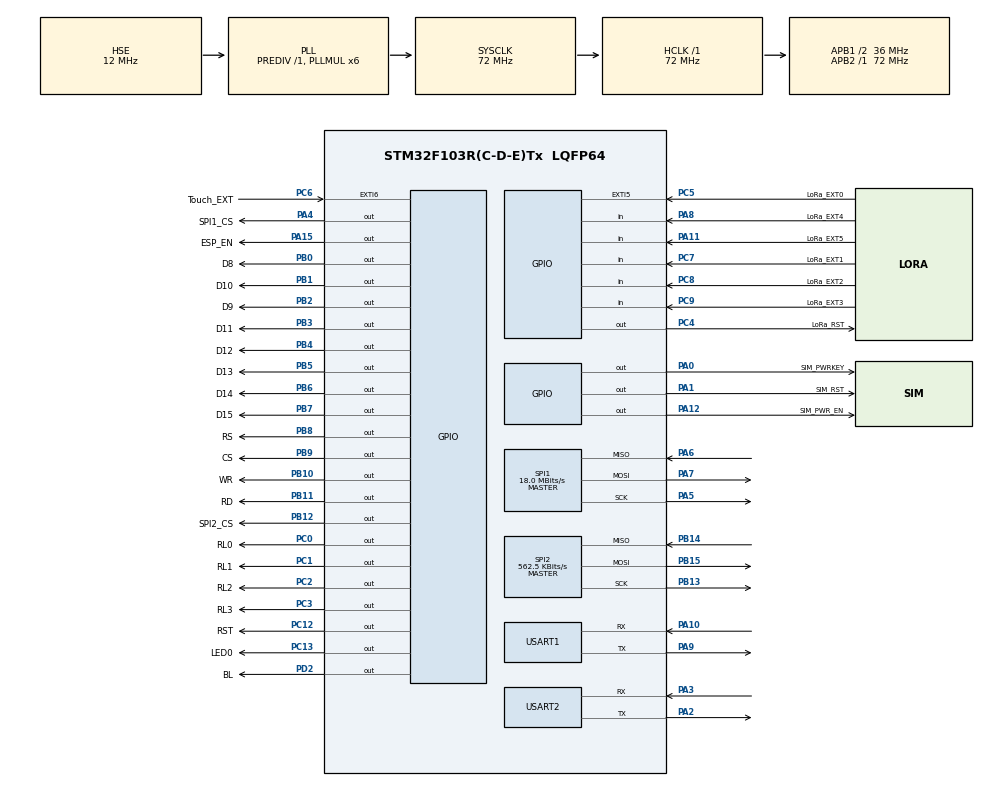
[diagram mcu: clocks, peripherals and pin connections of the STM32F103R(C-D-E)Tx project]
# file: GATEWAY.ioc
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FREERTOS.Tasks01=Task0,8,256,Task0Func,Default,NULL,Dynamic,NULL,NULL;Task1,24,512,Task1Func,Default,NULL,Dynamic,NULL,NULL;Task2,32,512,Task2Func,Default,NULL,Dynamic,NULL,NULL;Task3,16,512,Task3Func,Default,NULL,Dynamic,NULL,NULL
FREERTOS.configGENERATE_RUN_TIME_STATS=1
FREERTOS.configMINIMAL_STACK_SIZE=128
FREERTOS.configRECORD_STACK_HIGH_ADDRESS=1
FREERTOS.configTOTAL_HEAP_SIZE=10000
FREERTOS.configUSE_IDLE_HOOK=0
FREERTOS.configUSE_NEWLIB_REENTRANT=0
FREERTOS.configUSE_TICKLESS_IDLE=0
Mcu.Family=STM32F1
Mcu.Name=STM32F103R(C-D-E)Tx
Mcu.Package=LQFP64
NVIC.EXTI9_5_IRQn=true\:8\:0\:true\:false\:true\:true\:true\:true\:true
NVIC.PriorityGroup=NVIC_PRIORITYGROUP_4
NVIC.SPI1_IRQn=true\:5\:0\:false\:false\:true\:true\:true\:true\:true
NVIC.SPI2_IRQn=true\:5\:0\:false\:false\:true\:true\:true\:true\:true
NVIC.TIM1_UP_IRQn=true\:15\:0\:false\:false\:true\:false\:false\:true\:true
NVIC.TIM4_IRQn=true\:5\:0\:false\:false\:true\:true\:true\:true\:true
NVIC.TIM5_IRQn=true\:5\:0\:false\:false\:true\:true\:true\:true\:true
NVIC.TIM6_IRQn=true\:5\:0\:false\:false\:true\:true\:true\:true\:true
NVIC.TIM7_IRQn=true\:5\:0\:false\:false\:true\:true\:true\:true\:true
NVIC.TimeBase=TIM1_UP_IRQn
NVIC.TimeBaseIP=TIM1
NVIC.USART1_IRQn=true\:5\:0\:false\:false\:true\:true\:true\:true\:true
NVIC.USART2_IRQn=true\:5\:0\:false\:false\:true\:true\:true\:true\:true
PA0-WKUP.GPIO_Label=SIM_PWRKEY
PA0-WKUP.Signal=GPIO_Output
PA1.GPIO_Label=SIM_RST
PA1.Signal=GPIO_Output
PA10.Mode=Asynchronous
PA10.Signal=USART1_RX
PA11.GPIO_Label=LoRa_EXT5
PA11.Signal=GPIO_Input
PA12.GPIO_Label=SIM_PWR_EN
PA12.Signal=GPIO_Output
PA13.Mode=Serial_Wire
PA13.Signal=SYS_JTMS-SWDIO
PA14.Mode=Serial_Wire
PA14.Signal=SYS_JTCK-SWCLK
PA15.GPIO_Label=ESP_EN
PA15.GPIO_PuPd=GPIO_NOPULL
PA15.Signal=GPIO_Output
PA2.Mode=Asynchronous
PA2.Signal=USART2_TX
PA3.Mode=Asynchronous
PA3.Signal=USART2_RX
PA4.GPIO_Label=SPI1_CS
PA4.GPIO_Speed=GPIO_SPEED_FREQ_HIGH
PA4.Signal=GPIO_Output
PA5.Mode=Full_Duplex_Master
PA5.Signal=SPI1_SCK
PA6.Mode=Full_Duplex_Master
PA6.Signal=SPI1_MISO
PA7.Mode=Full_Duplex_Master
PA7.Signal=SPI1_MOSI
PA8.GPIO_Label=LoRa_EXT4
PA8.Signal=GPIO_Input
PA9.Mode=Asynchronous
PA9.Signal=USART1_TX
PB0.GPIO_Label=D8
PB0.GPIO_Speed=GPIO_SPEED_FREQ_HIGH
PB0.PinState=GPIO_PIN_SET
PB0.Signal=GPIO_Output
PB1.GPIO_Label=D10
PB1.GPIO_Speed=GPIO_SPEED_FREQ_HIGH
PB1.PinState=GPIO_PIN_SET
PB1.Signal=GPIO_Output
PB10.GPIO_Label=WR
PB10.GPIO_Speed=GPIO_SPEED_FREQ_HIGH
PB10.Signal=GPIO_Output
PB11.GPIO_Label=RD
PB11.GPIO_PuPd=GPIO_NOPULL
PB11.GPIO_Speed=GPIO_SPEED_FREQ_HIGH
PB11.Signal=GPIO_Output
PB12.GPIO_Label=SPI2_CS
PB12.GPIO_Speed=GPIO_SPEED_FREQ_HIGH
PB12.Signal=GPIO_Output
PB13.Mode=Full_Duplex_Master
PB13.Signal=SPI2_SCK
PB14.Mode=Full_Duplex_Master
PB14.Signal=SPI2_MISO
PB15.Mode=Full_Duplex_Master
PB15.Signal=SPI2_MOSI
PB2.GPIO_Label=D9
PB2.GPIO_Speed=GPIO_SPEED_FREQ_HIGH
PB2.PinState=GPIO_PIN_SET
PB2.Signal=GPIO_Output
PB3.GPIO_Label=D11
PB3.GPIO_Speed=GPIO_SPEED_FREQ_HIGH
PB3.PinState=GPIO_PIN_SET
PB3.Signal=GPIO_Output
PB4.GPIO_Label=D12
PB4.GPIO_Speed=GPIO_SPEED_FREQ_HIGH
PB4.PinState=GPIO_PIN_SET
PB4.Signal=GPIO_Output
PB5.GPIO_Label=D13
PB5.GPIO_Speed=GPIO_SPEED_FREQ_HIGH
PB5.PinState=GPIO_PIN_SET
PB5.Signal=GPIO_Output
PB6.GPIO_Label=D14
PB6.GPIO_Speed=GPIO_SPEED_FREQ_HIGH
PB6.PinState=GPIO_PIN_SET
PB6.Signal=GPIO_Output
PB7.GPIO_Label=D15
PB7.GPIO_Speed=GPIO_SPEED_FREQ_HIGH
PB7.PinState=GPIO_PIN_SET
PB7.Signal=GPIO_Output
PB8.GPIO_Label=RS
PB8.GPIO_Speed=GPIO_SPEED_FREQ_HIGH
PB8.Signal=GPIO_Output
PB9.GPIO_Label=CS
PB9.GPIO_Speed=GPIO_SPEED_FREQ_HIGH
PB9.Signal=GPIO_Output
PC0.GPIO_Label=RL0
PC0.GPIO_Speed=GPIO_SPEED_FREQ_LOW
PC0.Signal=GPIO_Output
PC1.GPIO_Label=RL1
PC1.Signal=GPIO_Output
PC12.GPIO_Label=RST
PC12.GPIO_Speed=GPIO_SPEED_FREQ_MEDIUM
PC12.PinState=GPIO_PIN_RESET
PC12.Signal=GPIO_Output
PC13-TAMPER-RTC.GPIO_Label=LED0
PC13-TAMPER-RTC.Signal=GPIO_Output
PC2.GPIO_Label=RL2
PC2.Signal=GPIO_Output
PC3.GPIO_Label=RL3
PC3.Signal=GPIO_Output
PC4.GPIO_Label=LoRa_RST
PC4.GPIO_Speed=GPIO_SPEED_FREQ_HIGH
PC4.Signal=GPIO_Output
PC5.GPIO_Label=LoRa_EXT0
PC5.GPIO_ModeDefaultEXTI=GPIO_MODE_IT_RISING
PC5.GPIO_PuPd=GPIO_PULLDOWN
PC5.Signal=GPXTI5
PC6.GPIO_Label=Touch_EXT
PC6.GPIO_ModeDefaultEXTI=GPIO_MODE_IT_FALLING
PC6.GPIO_PuPd=GPIO_PULLUP
PC6.Signal=GPXTI6
PC7.GPIO_Label=LoRa_EXT1
PC7.Signal=GPIO_Input
PC8.GPIO_Label=LoRa_EXT2
PC8.Signal=GPIO_Input
PC9.GPIO_Label=LoRa_EXT3
PC9.Signal=GPIO_Input
PD0-OSC_IN.Mode=HSE-External-Oscillator
PD0-OSC_IN.Signal=RCC_OSC_IN
PD1-OSC_OUT.Mode=HSE-External-Oscillator
PD1-OSC_OUT.Signal=RCC_OSC_OUT
PD2.GPIO_Label=BL
PD2.GPIO_PuPd=GPIO_PULLDOWN
PD2.GPIO_Speed=GPIO_SPEED_FREQ_MEDIUM
PD2.Signal=GPIO_Output
ProjectManager.HeapSize=0x200
ProjectManager.StackSize=0x400
ProjectManager.TargetToolchain=Makefile
RCC.AHBFreq_Value=72000000
RCC.APB1CLKDivider=RCC_HCLK_DIV2
RCC.APB1Freq_Value=36000000
RCC.APB1TimFreq_Value=72000000
RCC.APB2Freq_Value=72000000
RCC.APB2TimFreq_Value=72000000
RCC.HCLKFreq_Value=72000000
RCC.HSE_VALUE=12000000
RCC.PLLMUL=RCC_PLL_MUL6
RCC.PLLSourceVirtual=RCC_PLLSOURCE_HSE
RCC.SYSCLKFreq_VALUE=72000000
RCC.SYSCLKSource=RCC_SYSCLKSOURCE_PLLCLK
RCC.USBFreq_Value=48000000
RCC.USBPrescaler=RCC_USBCLKSOURCE_PLL_DIV1_5
RTC.Date=15
RTC.Format=RTC_FORMAT_BIN
RTC.Hours=19
RTC.Minutes=30
RTC.Month=RTC_MONTH_JULY
RTC.WeekDay=RTC_WEEKDAY_SATURDAY
RTC.Year=7
SPI1.BaudRatePrescaler=SPI_BAUDRATEPRESCALER_4
SPI1.CalculateBaudRate=18.0 MBits/s
SPI1.Direction=SPI_DIRECTION_2LINES
SPI1.Mode=SPI_MODE_MASTER
SPI1.VirtualType=VM_MASTER
SPI2.BaudRatePrescaler=SPI_BAUDRATEPRESCALER_64
SPI2.CalculateBaudRate=562.5 KBits/s
SPI2.Direction=SPI_DIRECTION_2LINES
SPI2.Mode=SPI_MODE_MASTER
SPI2.VirtualType=VM_MASTER
TIM4.Period=49999
TIM4.Prescaler=7199
TIM5.Period=99
TIM5.Prescaler=71
TIM6.Period=19999
TIM6.Prescaler=719
TIM7.Period=19999
TIM7.Prescaler=719
USART1.VirtualMode=VM_ASYNC
USART2.VirtualMode=VM_ASYNC
VP_FREERTOS_VS_CMSIS_V2.Mode=CMSIS_V2
VP_RTC_No_RTC_Output.Mode=RTC_OUT_NO
VP_RTC_VS_RTC_Activate.Mode=RTC_Enabled
VP_RTC_VS_RTC_Calendar.Mode=RTC_Calendar
VP_SYS_VS_tim1.Mode=TIM1
VP_TIM4_VS_ClockSourceINT.Mode=Internal
VP_TIM5_VS_ClockSourceINT.Mode=Internal
VP_TIM6_VS_ClockSourceINT.Mode=Enable_Timer
VP_TIM7_VS_ClockSourceINT.Mode=Enable_Timer
board=custom

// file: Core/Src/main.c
/* USER CODE BEGIN Header */
/**
  ******************************************************************************
  * @file           : main.c
  * @brief          : Main program body
  ******************************************************************************
  * @attention
  *
  * Copyright (c) 2023 STMicroelectronics.
  * All rights reserved.
  *
  * This software is licensed under terms that can be found in the LICENSE file
  * in the root directory of this software component.
  * If no LICENSE file comes with this software, it is provided AS-IS.
  *
  ******************************************************************************
  */
/* USER CODE END Header */
#include "main.h"
#include "cmsis_os.h"
#include "rtc.h"
#include "spi.h"
#include "tim.h"
#include "usart.h"
#include "gpio.h"

/* USER CODE BEGIN Includes */
#include "event_groups.h"
#include "common.h"
/* USER CODE END Includes */

void SystemClock_Config(void);
void MX_FREERTOS_Init(void);

int main(void)
{

  /* MCU Configuration--------------------------------------------------------*/

  /* Reset of all peripherals, Initializes the Flash interface and the Systick. */
  HAL_Init();

  /* Configure the system clock */
  SystemClock_Config();

  /* Initialize all configured peripherals */
  MX_GPIO_Init();
  MX_SPI1_Init();
  MX_SPI2_Init();
  MX_USART2_UART_Init();
  MX_RTC_Init();
  MX_USART1_UART_Init();
  MX_TIM7_Init();
  MX_TIM6_Init();
  MX_TIM5_Init();
  MX_TIM4_Init();
  /* USER CODE BEGIN 2 */
  NVIC_SetPriorityGrouping( NVIC_PRIORITYGROUP_4 );
  /* USER CODE END 2 */

  /* Init scheduler */
  osKernelInitialize();  /* Call init function for freertos objects (in freertos.c) */
  MX_FREERTOS_Init();

  /* Start scheduler */
  osKernelStart();
  /* We should never get here as control is now taken by the scheduler */
  /* Infinite loop */
  while (1)
  {

  }
}

void SystemClock_Config(void)
{
  RCC_OscInitTypeDef RCC_OscInitStruct = {0};
  RCC_ClkInitTypeDef RCC_ClkInitStruct = {0};
  RCC_PeriphCLKInitTypeDef PeriphClkInit = {0};

  /** Initializes the RCC Oscillators according to the specified parameters
  * in the RCC_OscInitTypeDef structure.
  */
  RCC_OscInitStruct.OscillatorType = RCC_OSCILLATORTYPE_LSI|RCC_OSCILLATORTYPE_HSE;
  RCC_OscInitStruct.HSEState = RCC_HSE_ON;
  RCC_OscInitStruct.HSEPredivValue = RCC_HSE_PREDIV_DIV1;
  RCC_OscInitStruct.HSIState = RCC_HSI_ON;
  RCC_OscInitStruct.LSIState = RCC_LSI_ON;
  RCC_OscInitStruct.PLL.PLLState = RCC_PLL_ON;
  RCC_OscInitStruct.PLL.PLLSource = RCC_PLLSOURCE_HSE;
  RCC_OscInitStruct.PLL.PLLMUL = RCC_PLL_MUL6;
  if (HAL_RCC_OscConfig(&RCC_OscInitStruct) != HAL_OK)
  {
    Error_Handler();
  }

  /** Initializes the CPU, AHB and APB buses clocks
  */
  RCC_ClkInitStruct.ClockType = RCC_CLOCKTYPE_HCLK|RCC_CLOCKTYPE_SYSCLK
                              |RCC_CLOCKTYPE_PCLK1|RCC_CLOCKTYPE_PCLK2;
  RCC_ClkInitStruct.SYSCLKSource = RCC_SYSCLKSOURCE_PLLCLK;
  RCC_ClkInitStruct.AHBCLKDivider = RCC_SYSCLK_DIV1;
  RCC_ClkInitStruct.APB1CLKDivider = RCC_HCLK_DIV2;
  RCC_ClkInitStruct.APB2CLKDivider = RCC_HCLK_DIV1;

  if (HAL_RCC_ClockConfig(&RCC_ClkInitStruct, FLASH_LATENCY_2) != HAL_OK)
  {
    Error_Handler();
  }
  PeriphClkInit.PeriphClockSelection = RCC_PERIPHCLK_RTC;
  PeriphClkInit.RTCClockSelection = RCC_RTCCLKSOURCE_LSI;
  if (HAL_RCCEx_PeriphCLKConfig(&PeriphClkInit) != HAL_OK)
  {
    Error_Handler();
  }
}

/* USER CODE BEGIN 4 */

extern bool is_UART1_RX_Done;
extern bool is_UART2_RX_Done;
extern uint64_t traceTime;

/* USER CODE END 4 */

void HAL_TIM_PeriodElapsedCallback(TIM_HandleTypeDef *htim)
{
  /* USER CODE BEGIN Callback 0 */
  if (htim->Instance == TIM7)
  {
    is_UART1_RX_Done = true;
    HAL_TIM_Base_Stop_IT(&htim7);
  }

  if (htim->Instance == TIM6)
  {
    is_UART2_RX_Done = true;
    HAL_TIM_Base_Stop_IT(&htim6);
  }

  if (htim->Instance == TIM5)
  {
    traceTime++;
  }

  if (htim->Instance == TIM4)
  {
    App_Refresh_Tick();
  }

  /* USER CODE END Callback 0 */
  if (htim->Instance == TIM1) {
    HAL_IncTick();
  }
}

void Error_Handler(void)
{
  __disable_irq();
  while (1)
  {
  }
}

#ifdef  USE_FULL_ASSERT
/**
  * @brief  Reports the name of the source file and the source line number
  *         where the assert_param error has occurred.
  * @param  file: pointer to the source file name
  * @param  line: assert_param error line source number
  * @retval None
  */
void assert_failed(uint8_t *file, uint32_t line)
{
  /* USER CODE BEGIN 6 */
  /* User can add his own implementation to report the file name and line number,
     ex: printf("Wrong parameters value: file %s on line %d\r\n", file, line) */
  logPC("Wrong parameters value: file %s on line %d", file, line);
  /* USER CODE END 6 */
}
#endif /* USE_FULL_ASSERT */

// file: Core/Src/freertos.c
/* USER CODE BEGIN Header */
/**
 ******************************************************************************
 * File Name          : freertos.c
 * Description        : Code for freertos applications
 ******************************************************************************
 * @attention
 *
 * Copyright (c) 2023 STMicroelectronics.
 * All rights reserved.
 *
 * This software is licensed under terms that can be found in the LICENSE file
 * in the root directory of this software component.
 * If no LICENSE file comes with this software, it is provided AS-IS.
 *
 ******************************************************************************
 */
/* USER CODE END Header */

#include "FreeRTOS.h"
#include "task.h"
#include "main.h"
#include "cmsis_os.h"

/* USER CODE BEGIN Includes */

#include "stdio.h"
#include "string.h"
#include "event_groups.h"
#include "semphr.h"

#include "usart.h"
#include "tim.h"
#include "rtc.h"

#include "lcd.h"
#include "pic.h"
#include "sx1278.h"
#include "common.h"
#include "sim.h"
#include "flash.h"
#include "button.h"
#include "mqtt.h"

/* USER CODE END Includes */

/* USER CODE BEGIN PTD */

typedef struct LoRa_Link_Struct
{
  uint16_t Node_ID;
  uint16_t Node_Status;
  uint16_t Node_Battery_Voltage;
  uint16_t Node_Period;
} Link_Struct_t;

typedef struct LoRa_Data_Struct
{
  Link_Struct_t Link;
  uint16_t Node_Soil_Temperature;
  uint16_t Node_Air_Temperature;
  uint16_t Node_Soil_Humidity;
  uint16_t Node_Air_Humidity;
  uint16_t Node_Salinity;
  uint16_t Node_Conductivity;
  uint16_t Node_pH;
  uint16_t Node_N;
  uint16_t Node_P;
  uint16_t Node_K;
} Data_Struct_t;

typedef struct LoRa_Packet_ID_0
{
  uint16_t Packet_ID;
  Link_Struct_t Payload;
} Link_Packet_t;

typedef struct LoRa_Packet_ID_1
{
  uint16_t Packet_ID;
  Data_Struct_t Payload;
} Data_Packet_t;

typedef struct LoRa_Packet_ID_2
{
  uint16_t Packet_ID;
  uint16_t Target_Node_ID;
  uint16_t Target_Node_Status;
  uint16_t Target_Node_Period;
  uint16_t Target_Node_Response;
} ResponsePacket_t;

typedef enum NodeStatus
{
  WAKEUP_MODE = 1U,
  LINK_MODE = 2U,
  NORMAL_MODE = 4U,
  RETRY_MODE = 8U,
  SHUTDOWN_MODE = 16U
} NodeStatus_t;

typedef enum Page_Enum
{
  MAIN_PAGE = 0U,
  JOIN_REQUEST_PAGE = 1U,
  NETWORK_PAGE = 2U,
  NODE_PAGE = 3U,
  CONTROL_PAGE = 4U,
  FAKE_PAGE = 133U
} Page_t;

typedef struct Time_Struct
{
  int	tm_sec;
  int	tm_min;
  int	tm_hour;
  int	tm_mday;
  int	tm_mon;
  int	tm_year;
  int	tm_wday;
  int	tm_yday;
  int	tm_isdst;
} Time_t;

/* USER CODE END PTD */

/* USER CODE BEGIN PD */

#define PACKET_ID_0   (0xAAAAU)
#define PACKET_ID_1   (0x5A5AU)
#define PACKET_ID_2   (0x5555U)

#define LINK_ACCEPT   (0xAAU)
#define LINK_REJECT   (0x55U)

#define LINK_CARRYON  (0x00U)
#define LINK_DISMISS  (0xFFU)

#define LINK_ACK      (0xABU)
#define LINK_NACK     (0xBAU)

#define DEFAULT_PERIOD_SEC  (300U)

// DO NOT CHANGE
#define EVT_LORA      (0x04U)
#define EVT_TOCUH     (0x02U)

// DO NOT CHANGE
#define MAX_NODE      (50U)

// WARNING: DO NOT CHANGE
#define USE_WIFI      (true)
#define USE_4G        (false)

/* USER CODE END PD */

/* USER CODE BEGIN Variables */

static uint8_t rxBufferUART1[200] = {0};
volatile static uint8_t rxIndexUART1 = 0;

static uint8_t rxBufferUART2[200] = {0};
volatile static uint8_t rxIndexUART2 = 0;

volatile bool is_UART1_RX_Done = true;
volatile bool is_UART2_RX_Done = true;
volatile bool is_LCD_processing = false;
volatile bool is_LoRa_processing = false;
volatile bool is_4G_or_WiFi = USE_WIFI;
volatile bool is_4G_connected = false;
volatile bool is_WiFi_connected = false;
volatile bool is_MQTT_connected = false;
volatile bool is_MQTT_update = false;
volatile bool is_promt_window_on = false;
volatile bool is_page_change = false;

static Data_Struct_t Node_Table[MAX_NODE] = {0};
static uint8_t number_of_Node_inNetwork = 0;
static uint8_t number_of_Node_inQueue = 0;
static uint8_t number_of_Response_Packet_inQueue = 0;
static uint16_t selected_Node_ID = 0;
static uint16_t updated_Node_ID = 0;

static EventGroupHandle_t evt_group;
static BaseType_t xHigherPriorityTaskWoken = pdFALSE;
static QueueHandle_t link_queue;
static QueueHandle_t response_queue;

volatile uint64_t traceTime = 0;

static Page_t Current_Page = MAIN_PAGE;
static uint16_t arrayNodeDisplay[4] = {0};
static char tempString[50] = {0};

const char link_mode_string[] = "LINK";
const char normal_mode_string[] = "NORMAL";
const char retry_mode_string[] = "RETRY";

/* USER CODE END Variables */
/* Definitions for Task0 */
osThreadId_t Task0Handle;
const osThreadAttr_t Task0_attributes = {
  .name = "Task0",
  .stack_size = 256 * 4,
  .priority = (osPriority_t) osPriorityLow,
};
/* Definitions for Task1 */
osThreadId_t Task1Handle;
const osThreadAttr_t Task1_attributes = {
  .name = "Task1",
  .stack_size = 512 * 4,
  .priority = (osPriority_t) osPriorityNormal,
};
/* Definitions for Task2 */
osThreadId_t Task2Handle;
const osThreadAttr_t Task2_attributes = {
  .name = "Task2",
  .stack_size = 512 * 4,
  .priority = (osPriority_t) osPriorityAboveNormal,
};
/* Definitions for Task3 */
osThreadId_t Task3Handle;
const osThreadAttr_t Task3_attributes = {
  .name = "Task3",
  .stack_size = 512 * 4,
  .priority = (osPriority_t) osPriorityBelowNormal,
};

/* USER CODE BEGIN FunctionPrototypes */

bool App_Add_Node_To_Network(Link_Struct_t link);
bool App_Delete_Node_From_Network(uint16_t Node_ID);

void App_SIM_MQTT_Parser(void);
void App_ESP_MQTT_Parser(void);

void App_ESP_getTime(void);

bool is_Node_ID_inLinkQueue(uint16_t Node_ID, bool remove);
bool is_Node_ID_inResponseQueue(uint16_t Node_ID, bool remove);
bool is_Node_ID_inNetwork(uint16_t Node_ID);
uint8_t get_Index_from_Node_ID(uint16_t Node_ID);
void LoRa_Packet_Parser(const uint8_t* data, uint32_t len);

void LCD_Print_Promt_Window(void);

void LCD_Print_Join_Request_Page(void);
void LCD_Join_Request_Page_Handle(const uint16_t x, const uint16_t y);

void LCD_Print_Main_Page(void);
void LCD_Main_Page_Handle(const uint16_t x, const uint16_t y);

void LCD_Print_Network_Page(void);
void LCD_Network_Page_Handle(const uint16_t x, const uint16_t y);

void LCD_Print_Node_Page(void);
void LCD_Node_Page_Handle(const uint16_t x, const uint16_t y);

void LCD_Print_Control_Page(void);
void LCD_Control_Page_Handle(const uint16_t x, const uint16_t y);

void LCD_Print_Fake_Page(void);
void LCD_Fake_Page_Handle(const uint16_t x, const uint16_t y);

/* USER CODE END FunctionPrototypes */

void Task0Func(void *argument);
void Task1Func(void *argument);
void Task2Func(void *argument);
void Task3Func(void *argument);

void MX_FREERTOS_Init(void); /* (MISRA C 2004 rule 8.1) */

/* Hook prototypes */
void configureTimerForRunTimeStats(void);
unsigned long getRunTimeCounterValue(void);

/* USER CODE BEGIN 1 */
/* Functions needed when configGENERATE_RUN_TIME_STATS is on */
__weak void configureTimerForRunTimeStats(void)
{
  HAL_TIM_Base_Start_IT(&htim5);
}

__weak unsigned long getRunTimeCounterValue(void)
{
  // uint32_t counter_now = __HAL_TIM_GetCounter(&htim5);
  // HAL_TIM_Base_Stop(&htim5);
  // __HAL_TIM_SET_COUNTER(&htim5, 0U);
  // HAL_TIM_Base_Start(&htim5);
  return traceTime;
}
/* USER CODE END 1 */

void MX_FREERTOS_Init(void) {
  /* USER CODE BEGIN Init */

  HAL_Delay(1500);
  Log_Init();
  /* USER CODE END Init */

  /* USER CODE BEGIN RTOS_SEMAPHORES */
  // lcd_semaphore = xSemaphoreCreateBinary();
  /* add semaphores, ... */
  /* USER CODE END RTOS_SEMAPHORES */

  /* Create the thread(s) */
  /* creation of Task0 */
  Task0Handle = osThreadNew(Task0Func, NULL, &Task0_attributes);

  /* creation of Task1 */
  Task1Handle = osThreadNew(Task1Func, NULL, &Task1_attributes);

  /* creation of Task2 */
  Task2Handle = osThreadNew(Task2Func, NULL, &Task2_attributes);

  /* creation of Task3 */
  Task3Handle = osThreadNew(Task3Func, NULL, &Task3_attributes);

  /* USER CODE BEGIN RTOS_THREADS */
  if ((Task0Handle == NULL) || (Task1Handle == NULL) || (Task2Handle == NULL) || (Task3Handle == NULL)) while(1);
  /* add threads, ... */
  /* USER CODE END RTOS_THREADS */

  /* USER CODE BEGIN RTOS_EVENTS */
  evt_group = xEventGroupCreate();
  if (evt_group == NULL) while(1);
  xEventGroupClearBits(evt_group, 0xFF);

  link_queue = xQueueCreate(MAX_NODE, sizeof(Link_Struct_t));
  if (link_queue == NULL) while(1);

  response_queue = xQueueCreate(5U, sizeof(ResponsePacket_t));
  if (response_queue == NULL) while(1);
  /* add events, ... */
  /* USER CODE END RTOS_EVENTS */

}

/* USER CODE BEGIN Header_Task0Func */
/**
 * @brief  Function implementing the Task0 thread.
 *
 *  This is the task to process UART (including ESP32) and helper functionalities
 *
 * @param  argument: Not used
 * @retval None
 */
/* USER CODE END Header_Task0Func */
void Task0Func(void *argument)
{
  /* USER CODE BEGIN Task0Func */
  static const char *TAG_LCD = "Utility";

  HAL_GPIO_WritePin(LED0_GPIO_Port, LED0_Pin, GPIO_PIN_RESET);
  HAL_Delay(200);
  HAL_GPIO_WritePin(LED0_GPIO_Port, LED0_Pin, GPIO_PIN_SET);

  HAL_UART_Receive_IT(&huart1, &rxBufferUART1[rxIndexUART1++], sizeof(uint8_t));

  HAL_TIM_Base_Stop_IT(&htim7);
  __HAL_TIM_SetCounter(&htim7, 0U);
  __HAL_TIM_CLEAR_IT(&htim7, TIM_IT_BREAK);

  HAL_UART_Receive_IT(&huart2, &rxBufferUART2[rxIndexUART2++], sizeof(uint8_t));

  HAL_TIM_Base_Stop_IT(&htim6);
  __HAL_TIM_SetCounter(&htim6, 0U);
  __HAL_TIM_CLEAR_IT(&htim6, TIM_IT_BREAK);

  static TaskStatus_t *pxTaskStatusArray;
	volatile static UBaseType_t uxArraySize, x;
	static unsigned long ulTotalRunTime;
	static float runtime_percent;

  HAL_Delay(500);

  if (is_4G_or_WiFi == USE_4G)    logPC("WIFI-OFF\t");
  if (is_4G_or_WiFi == USE_WIFI)  logPC("WIFI-ON\t");

  uint32_t timeKeeper0 = HAL_GetTick();
  uint32_t timeKeeper1 = HAL_GetTick();
  uint32_t timeKeeper2 = HAL_GetTick();
  /* Infinite loop */
  for (;;)
  {
    if ((is_UART1_RX_Done == true) && (rxIndexUART1 != 1))
    {
      logPC("UART1 RX - %s", rxBufferUART1);
      if      (strstr(rxBufferUART1, "WIFI-CONNECTED") != NULL)     {is_WiFi_connected = true;}
      else if (strstr(rxBufferUART1, "WIFI-DISCONNECTED") != NULL)  {is_WiFi_connected = false; is_MQTT_connected = false;}
      else if (strstr(rxBufferUART1, "MQTT-CONNECTED") != NULL)     {is_MQTT_connected = true; is_WiFi_connected = true;}
      else if (strstr(rxBufferUART1, "MQTT-DISCONNECTED") != NULL)  {is_MQTT_connected = false;}
      if      (strstr(rxBufferUART1, "MQTT-DATA") != NULL)          {App_ESP_MQTT_Parser();};
      if      (strstr(rxBufferUART1, "TIME-") != NULL)              {App_ESP_getTime();};
      rxIndexUART1 = 0;
      memset(rxBufferUART1, '\0', sizeof(rxBufferUART1));
      HAL_UART_Abort_IT(&huart1);
      HAL_UART_Receive_IT(&huart1, &rxBufferUART1[rxIndexUART1++], sizeof(uint8_t));
      HAL_GPIO_WritePin(LED0_GPIO_Port, LED0_Pin, GPIO_PIN_SET);
    }

    if ((is_UART2_RX_Done == true) && (rxIndexUART2 != 1))
    {
      logPC("UART2 RX - %s", rxBufferUART2);
      SIM_GetResponse((const char*)rxBufferUART2);
      rxIndexUART2 = 0;
      memset(rxBufferUART2, '\0', sizeof(rxBufferUART2));
      HAL_UART_Abort_IT(&huart2);
      HAL_UART_Receive_IT(&huart2, &rxBufferUART2[rxIndexUART2++], sizeof(uint8_t));
      HAL_GPIO_WritePin(LED0_GPIO_Port, LED0_Pin, GPIO_PIN_SET);
    }

    if ((is_MQTT_update == true) && (is_Node_ID_inNetwork(updated_Node_ID) == true) && (is_4G_or_WiFi == USE_WIFI) && (is_WiFi_connected == true) && (is_MQTT_connected == true))
    {
      HAL_UART_Transmit(&huart1, "MQTT-", 5U, 100);
      HAL_UART_Transmit(&huart1, &Node_Table[get_Index_from_Node_ID(updated_Node_ID)], sizeof(Data_Struct_t), 100);
      updated_Node_ID = 0xFFFF;
      is_MQTT_update = false;
    }

    if ((HAL_GetTick() - timeKeeper0) >= 3000)
    {
      if (is_LCD_processing == true)  is_LCD_processing = false;
      if (is_LoRa_processing == true)
      {
        sx1278_start_recv_data();
        xEventGroupClearBits(evt_group, EVT_LORA);
        is_LoRa_processing = false;
      }
      timeKeeper0 = HAL_GetTick();
    }

    if ((HAL_GetTick() - timeKeeper1) >= 60000)
    {
      uxArraySize = uxTaskGetNumberOfTasks();
      pxTaskStatusArray = pvPortMalloc(uxArraySize * sizeof(TaskStatus_t)); // a little bit scary!
      if (pxTaskStatusArray != NULL)
      {
        uxArraySize = uxTaskGetSystemState(pxTaskStatusArray, uxArraySize, &ulTotalRunTime);

        logPC("Task count = %lu\n", uxArraySize);
        logPC("No      Name          S Usage   HW\n");

        for (x = 0; x < uxArraySize; x++)
        {
          runtime_percent = (float) ((100 * (float)pxTaskStatusArray[x].ulRunTimeCounter) / (float)ulTotalRunTime);
          logPC("Task %lu: %-12s %2d %07.4f %4i\n", x, pxTaskStatusArray[x].pcTaskName, pxTaskStatusArray[x].eCurrentState, runtime_percent, pxTaskStatusArray[x].usStackHighWaterMark);
        }
        vPortFree(pxTaskStatusArray);
      }
      else  logPC("Unable to allocate stack space");
      timeKeeper1 = HAL_GetTick();
    }

    osDelay(10);
  }
  /* USER CODE END Task0Func */
}

/* USER CODE BEGIN Header_Task1Func */
/**
 * @brief Function implementing the Task1 thread.
 *
 *    This is the Task to process LCD display functionalities
 *
 * @param argument: Not used
 * @retval None
 */
/* USER CODE END Header_Task1Func */
void Task1Func(void *argument)
{
  /* USER CODE BEGIN Task1Func */
  static const char *TAG_LCD = "LCD";
  volatile static uint16_t coordinateX = 0;
  volatile static uint16_t coordinateY = 0;
  static EventBits_t evt_bits_lcd;
  xEventGroupClearBits(evt_group, EVT_TOCUH);

  ILI9341_Unselect();
  ILI9341_Init();
  LOG(TAG_LCD, "Initialize Done!\t");
  {
    uint32_t timeMark = HAL_GetTick();
    ILI9341_FillScreen(ILI9341_WHITE);
    timeMark = HAL_GetTick() - timeMark;
    logPC("%s - Screen Fill time: %d ms\tFPS: %2.1f\t", TAG_LCD, timeMark, (float)((1000.0)/(float)(timeMark)));
  }
  ILI9341_DrawImage(60, 45, 200, 150, (const uint16_t *)gLogoMain);
  osDelay(2000);
  // ILI9341_FillScreen(ILI9341_BLACK);
  is_page_change = true;
  LCD_Print_Main_Page();

  __HAL_TIM_SetCounter(&htim4, 0U);
  HAL_TIM_Base_Start_IT(&htim4);

  /* Infinite loop */
  for (;;)
  {
    evt_bits_lcd = xEventGroupWaitBits(evt_group, EVT_TOCUH, pdTRUE, pdFALSE, portMAX_DELAY);

    if(((evt_bits_lcd & EVT_TOCUH) != 0U) && (HAL_GPIO_ReadPin(Touch_EXT_GPIO_Port, Touch_EXT_Pin) == GPIO_PIN_RESET))
    {
      if (ILI9341_TouchGetCoordinates((uint16_t*)&coordinateX, (uint16_t*)&coordinateY) == true)
      {
        logPC("%s - Touched!\tCoordinate X - %d\tCoordinate Y - %d\t", TAG_LCD, coordinateX, coordinateY);
        switch (Current_Page)
        {
          case MAIN_PAGE: {
            LCD_Main_Page_Handle(coordinateX, coordinateY);
            break;
          }
          case JOIN_REQUEST_PAGE: {
            LCD_Join_Request_Page_Handle(coordinateX, coordinateY);
            break;
          }
          case NETWORK_PAGE: {
            LCD_Network_Page_Handle(coordinateX, coordinateY);
            break;
          }
          case NODE_PAGE: {
            LCD_Node_Page_Handle(coordinateX, coordinateY);
            break;
          }
          case CONTROL_PAGE: {
            LCD_Control_Page_Handle(coordinateX, coordinateY);
            break;
          }
          case FAKE_PAGE: {
            LCD_Fake_Page_Handle(coordinateX, coordinateY);
            break;
          }
          default: break;
        }
      }
    }

    // Refresh Page
    switch (Current_Page)
    {
      case MAIN_PAGE: {
        LCD_Print_Main_Page();
        break;
      }
      case JOIN_REQUEST_PAGE: {
        LCD_Print_Join_Request_Page();
        break;
      }
      case NETWORK_PAGE: {
        LCD_Print_Network_Page();
        break;
      }
      case NODE_PAGE: {
        LCD_Print_Node_Page();
        break;
      }
      case CONTROL_PAGE: {
        LCD_Print_Control_Page();
        break;
      }
      case FAKE_PAGE: {
        LCD_Print_Fake_Page();
        break;
      }
      default: break;
    }

    xEventGroupClearBits(evt_group, EVT_TOCUH);
    is_LCD_processing = false;
    osDelay(100);
  }
  /* USER CODE END Task1Func */
}

/* USER CODE BEGIN Header_Task2Func */
/**
 * @brief Function implementing the Task2 thread.
 *
 *    This is the Task to handle LoRa transceiver
 *
 * @param argument: Not used
 * @retval None
 */
/* USER CODE END Header_Task2Func */
void Task2Func(void *argument)
{
  /* USER CODE BEGIN Task2Func */
  static const char *TAG_LCD = "LoRa";
  static uint8_t data[100] = {0};
  static uint32_t nByteRx = 0;
  static int rssi = -1;
  static float snr = -1;
  static EventBits_t evt_bits;

  osDelay(1000);

  sx1278_init();
  sx1278_start_recv_data();

  /* Infinite loop */
  for (;;)
  {
    xEventGroupClearBits(evt_group, EVT_LORA);
    evt_bits = xEventGroupWaitBits(evt_group, EVT_LORA, pdTRUE, pdFALSE, portMAX_DELAY);

    if(((evt_bits & EVT_LORA) != 0U) && (HAL_GPIO_ReadPin(LoRa_EXT0_GPIO_Port, LoRa_EXT0_Pin) == GPIO_PIN_SET))
    {
      if (sx1278_recv_data((uint8_t *)data, &nByteRx, &rssi, &snr, true) == SX1278_OK)
      {
        logPC("LoRa Received %d byte(s)\trssi: %d\tsnr: %2.1f\n", nByteRx, rssi, snr);
        logPC("LoRa payload:\t");
        for (int i = 0; i < nByteRx; i++)
        {
          logPC("%02X ", data[i]);
        }
        LoRa_Packet_Parser((const uint8_t*)data, nByteRx);
      }
    }
    xEventGroupClearBits(evt_group, EVT_LORA);
    is_LoRa_processing = false;
    osDelay(1);
  }
  /* USER CODE END Task2Func */
}

/* USER CODE BEGIN Header_Task3Func */
/**
* @brief Function implementing the Task3 thread.
*
*     This is the Task to handle SIM4G functionalities
*
* @param argument: Not used
* @retval None
*/
/* USER CODE END Header_Task3Func */
void Task3Func(void *argument)
{
  /* USER CODE BEGIN Task3Func */
  static char temp[2][200];
  static char * pChar = NULL;
  static uint32_t len = 0;
  static Data_Struct_t data_to_send;
  static const char *TAG_LCD = "SIM";

  if (is_4G_or_WiFi != USE_4G)  osThreadTerminate(Task3Handle);

  osDelay(CMD_DELAY_SHORT);
  if (SIM_Init() == true)
  {
    if (SIM_checkSignalStrength() != 99U) {logPC("SIM signal OK");}
    else                                  {logPC("SIM signal FAIL");}

    if (SIM_startGPRS() == true)  {logPC("SIM 4G OK");}
    else                          {logPC("SIM 4G FAIL");}
  }
  osDelay(CMD_DELAY_SHORT);
  if (MQTT_Connect() == true)
  {
    setMQTT_Callback(MQTT_Callback);
    MQTT_Sub("SolGarden/Gateway/0x2508");
  }

  is_4G_connected = true;
  is_MQTT_connected = true;

  uint32_t timeKeeper = HAL_GetTick();

  /* Infinite loop */
  for(;;)
  {
    if ((HAL_GetTick() - timeKeeper) >= 30000)
    {
      MQTT_PingReq();
      timeKeeper = HAL_GetTick();
    }

    if ((is_4G_connected == true) && (is_MQTT_connected == true) && (is_MQTT_update == true) && (is_Node_ID_inNetwork(updated_Node_ID) == true))
    {
      memset(temp, '\0', sizeof(temp));

      data_to_send = Node_Table[get_Index_from_Node_ID(updated_Node_ID)];

      if      (data_to_send.Link.Node_Status == LINK_MODE)    pChar = &link_mode_string;
      else if (data_to_send.Link.Node_Status == NORMAL_MODE)  pChar = &normal_mode_string;
      else if (data_to_send.Link.Node_Status == RETRY_MODE)   pChar = &retry_mode_string;
      else                                                    {logPC("Invalid Status"); continue;}

      sprintf(&temp[0], "SolGarden/Node/%04X/link", data_to_send.Link.Node_ID);
      len = sprintf(  &temp[1], "[{\"Node ID\": \"0x%04X\",\"Node Mode\": \"%s\",\"Battery Voltage\": %d,\"Period\": %d}]",
                      data_to_send.Link.Node_ID,
                      pChar,
                      data_to_send.Link.Node_Battery_Voltage,
                      data_to_send.Link.Node_Period);
      logPC("MQTT - Topic: '%s'", temp[0]);
      logPC("MQTT - Payload: '%s'", temp[1]);
      MQTT_Pub(temp[0], temp[1]);

      memset(temp, '\0', sizeof(temp));
      osDelay(500);

      sprintf(&temp[0], "SolGarden/Node/%04X/data", data_to_send.Link.Node_ID);
      len = sprintf(  &temp[1], "[{\"Soil Temp.\": %2.1f,\"Air Temp.\": %2.1f,\"Soil Humd.\": %2.1f,\"Air Humd.\": %2.1f,\"Salinity\": %d,\"Conductivity\": %d,\"pH\": %.1f,\"N\": %d,\"P\": %d,\"K\": %d}]",
                      (float)(data_to_send.Node_Soil_Temperature/10.0),
                      (float)(data_to_send.Node_Air_Temperature/10.0),
                      (float)(data_to_send.Node_Soil_Humidity/10.0),
                      (float)(data_to_send.Node_Air_Humidity/10.0),
                      (uint16_t)data_to_send.Node_Salinity,
                      (uint16_t)data_to_send.Node_Conductivity,
                      (float)(data_to_send.Node_pH/10.0),
                      (uint16_t)(data_to_send.Node_N/10),
                      (uint16_t)(data_to_send.Node_P/10),
                      (uint16_t)(data_to_send.Node_K/10));
      logPC("MQTT - Topic: '%s'", temp[0]);
      logPC("MQTT - Payload: '%s'", temp[1]);
      MQTT_Pub(temp[0], temp[1]);

      osDelay(500);
      updated_Node_ID = 0xFFFF;
      is_MQTT_update = false;
      timeKeeper = HAL_GetTick();
    }

    if (MQTT.mqttReceive.newEvent == 1)
    {
      logPC("Now parsing MQTT packet...");
      App_SIM_MQTT_Parser();
      MQTT.mqttReceive.newEvent = 0;
    }

    osDelay(200);
  }
  /* USER CODE END Task3Func */
}

/* USER CODE BEGIN Application */

void App_Refresh_Tick(void)
{
  HAL_TIM_Base_Stop_IT(&htim4);
  __HAL_TIM_SetCounter(&htim4, 0U);
  xEventGroupSetBitsFromISR(evt_group, EVT_TOCUH, &xHigherPriorityTaskWoken);
  is_LCD_processing = true;
  RTC_DateTypeDef DateToUpdate = {0};
  HAL_RTC_GetDate(&hrtc, &DateToUpdate, RTC_FORMAT_BIN);
  uint32_t reg = (DateToUpdate.WeekDay << 16U) | (DateToUpdate.Month << 12U) | (DateToUpdate.Date << 7U) | (DateToUpdate.Year);
  HAL_RTCEx_BKUPWrite(&hrtc, RTC_BKP_DR1, reg);
  HAL_TIM_Base_Start_IT(&htim4);
}

bool App_Add_Node_To_Network(Link_Struct_t link)
{
  if (number_of_Node_inNetwork == MAX_NODE) return false;
  for (int i = 0; i < MAX_NODE; i++)
  {
    if (Node_Table[i].Link.Node_ID == 0U)
    {
      Node_Table[i].Link = link;
      number_of_Node_inNetwork++;
      return true;
    }
  }
  return false;
}

bool App_Delete_Node_From_Network(uint16_t Node_ID)
{
  Data_Struct_t data = {0};
  memset(&data, '\0', sizeof(Data_Struct_t));
  for (int i = 0; i < MAX_NODE; i++)
  {
    if (Node_Table[i].Link.Node_ID == Node_ID)
    {
      Node_Table[i] = data;
      number_of_Node_inNetwork--;
      return true;
    }
  }
  return false;
}

bool App_Save_Data(Data_Struct_t data)
{
  // if ()
  for (int i = 0; i < MAX_NODE; i++)
  {
    if (Node_Table[i].Link.Node_ID == data.Link.Node_ID)
    {
      Node_Table[i] = data;
      return true;
    }
  }
  return false;
}

void App_SIM_MQTT_Parser(void)
{
  logPC("MQTT Receive through SIM\t");
}

void App_ESP_MQTT_Parser(void)
{
  logPC("MQTT Receive through ESP\t");
}

void App_ESP_getTime(void)
{
  Time_t timeNow = {0};
  RTC_TimeTypeDef sTime = {0};
  RTC_DateTypeDef sDate = {0};

  memcpy(&timeNow, (uint8_t*)strstr(rxBufferUART1, "TIME-")+5U, sizeof(Time_t));
  logPC("Getting time... Now is %02d/%02d/%02d %02d:%02d:%02d\t", timeNow.tm_mday, timeNow.tm_mon+1, timeNow.tm_year-100, timeNow.tm_hour, timeNow.tm_min, timeNow.tm_sec);

  sTime.Seconds = timeNow.tm_sec;
  sTime.Minutes = timeNow.tm_min;
  sTime.Hours = timeNow.tm_hour;

  sDate.Date = timeNow.tm_mday;
  sDate.Month = timeNow.tm_mon + 1;
  sDate.Year = timeNow.tm_year - 100;
  sDate.WeekDay = timeNow.tm_wday;

  if (HAL_RTC_SetTime(&hrtc, &sTime, RTC_FORMAT_BIN) != HAL_OK)  {Error_Handler();}
  if (HAL_RTC_SetDate(&hrtc, &sDate, RTC_FORMAT_BIN) != HAL_OK)  {Error_Handler();}
}

//-------------------------------------------------------------------------------------------------------------------

bool is_Node_ID_inLinkQueue(uint16_t Node_ID, bool remove)
{
  number_of_Node_inQueue = MAX_NODE - (uint8_t)uxQueueSpacesAvailable(link_queue);
  Link_Struct_t link_stored;
  for (int i = 0; i < number_of_Node_inQueue; i++)
  {
    xQueueReceive(link_queue, &link_stored, 100);
    if (link_stored.Node_ID == Node_ID)
    {
      if (remove == false)  xQueueSendToFront(link_queue, &link_stored, 100);
      return true;
    }
    else xQueueSend(link_queue, &link_stored, 100);
  }
  return false;
}

bool is_Node_ID_inResponseQueue(uint16_t Node_ID, bool remove)
{
  number_of_Response_Packet_inQueue = 5U - (uint8_t)uxQueueSpacesAvailable(response_queue);
  ResponsePacket_t resp_stored;
  for (int i = 0; i < number_of_Response_Packet_inQueue; i++)
  {
    xQueueReceive(response_queue, &resp_stored, 100);
    if (resp_stored.Target_Node_ID == Node_ID)
    {
      if (remove == false)  xQueueSendToFront(response_queue, &resp_stored, 100);
      return true;
    }
    else xQueueSend(response_queue, &resp_stored, 100);
  }
  return false;
}

bool is_Node_ID_inNetwork(uint16_t Node_ID)
{
  for (int i = 0; i < MAX_NODE; i++)
  {
    if (Node_Table[i].Link.Node_ID == Node_ID)  return true;
  }
  return false;
}

uint8_t get_Index_from_Node_ID(uint16_t Node_ID)
{
  if (Node_ID == 0)   return 0xFF;
  for (uint8_t i = 0; i < MAX_NODE; i++)
  {
    if (Node_Table[i].Link.Node_ID == Node_ID)  return i;
  }
  return 0xFF;
}

/**
 * @brief check communicate line for idle slot to talk
 *
 * @return true ok now TALK!
 * @return false <infinite loop with random delay time>
 */
bool listen_before_talk(void)
{
  EventBits_t evt_bits;
  uint8_t irq;
  uint32_t timeout = HAL_GetTick();
  is_LoRa_processing = false;
  while ((HAL_GetTick() - timeout) <= 4000)
  {
    xEventGroupClearBits(evt_group, EVT_LORA);
    sx1278_cad();
    evt_bits = xEventGroupWaitBits(evt_group, EVT_LORA, pdTRUE, pdFALSE, 1000);
    if ((evt_bits & EVT_LORA) != 0U)
    {
      logPC("LoRa - CAD Done\tTook: %i ms\t", HAL_GetTick() - timeout);
      irq = sx1278_read_reg(REG_IRQ_FLAGS);
      sx1278_write_reg(REG_IRQ_FLAGS, irq);
      if ((irq & 0x01) != 0U)
      {
        logPC("LoRa - CAD Detected\t");
        HAL_Delay(get_random_value(0, 50));
      }
      else
      {
        logPC("LoRa - CAD Clear\t");
        sx1278_set_irq(0x00);
        sx1278_standby();
        return true;
      }
    }
  }
  irq = sx1278_read_reg(REG_IRQ_FLAGS);
  sx1278_write_reg(REG_IRQ_FLAGS, irq);
  sx1278_set_irq(0x00);
  sx1278_standby();
  logPC("Listen FAIL...\t");
  return false;
}

void LoRa_Packet_Parser(const uint8_t* data, uint32_t len)
{
  // void *p = NULL;
  switch ((uint16_t)((data[0] << 8) & 0xFF00) | (uint16_t)(data[1] & 0x00FF))
  {
    case PACKET_ID_0: {
      if (len != sizeof(Link_Packet_t)) break;
      logPC("Link Packet\t");
      Link_Struct_t link_payload;
      memcpy((uint8_t *)&link_payload, (uint8_t *)&data[2], sizeof(Link_Struct_t));
      if ((is_Node_ID_inNetwork(link_payload.Node_ID) == true) && (is_Node_ID_inResponseQueue(link_payload.Node_ID, false) == false))
      {
        ResponsePacket_t resp = {PACKET_ID_2, link_payload.Node_ID, NORMAL_MODE, 180U, (uint16_t)(((LINK_ACCEPT << 8) & 0xFF00) | LINK_ACK)};
        xQueueSendToFront(response_queue, &resp, 100);
        logPC("Node already in Network -> Send promote!\t");
      }
      if (is_Node_ID_inResponseQueue(link_payload.Node_ID, false) == true)
      {
        ResponsePacket_t resp;
        xQueueReceive(response_queue, &resp, 100);
        if (resp.Target_Node_ID != link_payload.Node_ID)
        {
          logPC("Something went wrong...");
          xQueueSendToFront(response_queue, &resp, 100);
          break;
        }
        logPC("Response Ready...\t");
        if (listen_before_talk() == false)  xQueueSendToFront(response_queue, &resp, 100);
        else  {logPC("Sending packet...\t"); sx1278_send_data(&resp, sizeof(ResponsePacket_t)); logPC("Done!\n");}
        sx1278_start_recv_data();
        break;
      }
      if (is_Node_ID_inLinkQueue(link_payload.Node_ID, true) == false)  logPC("New Node! Send to Queue...\t");
      else                                                              logPC("Old Node...\t");
      xQueueSend(link_queue, &(link_payload), 100);
      number_of_Node_inQueue = MAX_NODE - (uint8_t)uxQueueSpacesAvailable(link_queue);
      if (number_of_Node_inQueue != MAX_NODE)   logPC("Link Queue has %d Node(s)\n", number_of_Node_inQueue);
      else                                      logPC("Link Queue Full\n");
      break;
    }
    case PACKET_ID_1: {
      if (len != sizeof(Data_Packet_t)) break;
      logPC("Data Packet\t");
      Data_Struct_t data_recv;
      memcpy((uint8_t *)&data_recv, (uint8_t *)&data[2], sizeof(Data_Struct_t));
      if (is_Node_ID_inNetwork(data_recv.Link.Node_ID) == true)
      {
        logPC("Node Registered -> Saving data... %s", (App_Save_Data(data_recv))? ("Success\t"):("Fail\t"));
        ResponsePacket_t resp = {PACKET_ID_2, data_recv.Link.Node_ID, NORMAL_MODE, 180U, (uint16_t)(((LINK_CARRYON << 8) & 0xFF00) | LINK_ACK)};
        logPC("Response Ready...\t");
        if (listen_before_talk() == false)  break;
        else  {logPC("Sending packet...\t"); sx1278_send_data(&resp, sizeof(ResponsePacket_t));}
        logPC("Done!\n");
        sx1278_start_recv_data();
        updated_Node_ID = data_recv.Link.Node_ID;
        is_MQTT_update = true;
      }
      else
      {
        logPC("Node Unregister -> Demote Node...\t");
        ResponsePacket_t resp = {PACKET_ID_2, data_recv.Link.Node_ID, LINK_MODE, 180U, (uint16_t)(((LINK_DISMISS << 8) & 0xFF00) | LINK_ACK)};
        logPC("Response Ready...\t");
        if (listen_before_talk() == false)  break;
        else  {logPC("Sending packet...\t"); sx1278_send_data(&resp, sizeof(ResponsePacket_t));}
        logPC("Done!\n");
        sx1278_start_recv_data();
      }
      break;
    }
    default: {
      logPC("???? Packet\n");
      break;
    }
  }
  return;
}

//-------------------------------------------------------------------------------------------------------------------

void HAL_GPIO_EXTI_Callback(uint16_t GPIO_Pin)
{
  if ((GPIO_Pin == LoRa_EXT0_Pin) && (HAL_GPIO_ReadPin(LoRa_EXT0_GPIO_Port, LoRa_EXT0_Pin) == GPIO_PIN_SET) && (is_LoRa_processing == false))
  {
    xEventGroupSetBitsFromISR(evt_group, EVT_LORA, &xHigherPriorityTaskWoken);
    is_LoRa_processing = true;
  }

  if ((GPIO_Pin == Touch_EXT_Pin) && (HAL_GPIO_ReadPin(Touch_EXT_GPIO_Port, Touch_EXT_Pin) == GPIO_PIN_RESET) && (is_LCD_processing == false))
  {
    xEventGroupSetBitsFromISR(evt_group, EVT_TOCUH, &xHigherPriorityTaskWoken);
    is_LCD_processing = true;
  }
}

void HAL_UART_RxCpltCallback(UART_HandleTypeDef *huart)
{
  if (huart->Instance == USART1)
  {
    HAL_TIM_Base_Stop_IT(&htim7);
    if ((is_UART1_RX_Done == true) && (rxIndexUART1 == 1))
    {
      HAL_GPIO_WritePin(LED0_GPIO_Port, LED0_Pin, GPIO_PIN_RESET);
      __HAL_TIM_CLEAR_IT(&htim7, TIM_IT_BREAK);
      is_UART1_RX_Done = false;
    }
    __HAL_TIM_SetCounter(&htim7, 0U);
    HAL_TIM_Base_Start_IT(&htim7);
    HAL_UART_Receive_IT(&huart1, &rxBufferUART1[rxIndexUART1++], sizeof(uint8_t));
  }

  if (huart->Instance == USART2)
  {
    HAL_TIM_Base_Stop_IT(&htim6);
    if ((is_UART2_RX_Done == true) && (rxIndexUART2 == 1))
    {
      HAL_GPIO_WritePin(LED0_GPIO_Port, LED0_Pin, GPIO_PIN_RESET);
      __HAL_TIM_CLEAR_IT(&htim6, TIM_IT_BREAK);
      is_UART2_RX_Done = false;
    }
    __HAL_TIM_SetCounter(&htim6, 0U);
    HAL_TIM_Base_Start_IT(&htim6);
    HAL_UART_Receive_IT(&huart2, &rxBufferUART2[rxIndexUART2++], sizeof(uint8_t));
  }
}

//-------------------------------------------------------------------------------------------------------------------

void LCD_Print_Promt_Window(void)
{
  if (Current_Page == JOIN_REQUEST_PAGE)
  {
    is_promt_window_on = true;
    ILI9341_UpdateButton(&Promt_Window);
    ILI9341_WriteString(Promt_Window.pos_x+12, Promt_Window.pos_y+10, "ALLOW REQUEST?", Font_11x18, ILI9341_RED, Promt_Window.color_on);
    sprintf(tempString, "Node ID %#04X", selected_Node_ID);
    ILI9341_WriteString(Promt_Window.pos_x+12, Promt_Window.pos_y+35, tempString, Font_11x18, ILI9341_BLACK, Promt_Window.color_on);
    ILI9341_UpdateButton(&Promt_Accept);
    ILI9341_WriteString(Promt_Accept.pos_x+7, Promt_Accept.pos_y+6, "Accept", Font_11x18, ILI9341_BLACK, Promt_Accept.color_on);
    ILI9341_UpdateButton(&Promt_Reject);
    ILI9341_WriteString(Promt_Reject.pos_x+7, Promt_Reject.pos_y+6, "Reject", Font_11x18, ILI9341_BLACK, Promt_Reject.color_on);
  }
  else if (Current_Page == NODE_PAGE)
  {
    is_promt_window_on = true;
    ILI9341_UpdateButton(&Promt_Window);
    ILI9341_WriteString(Promt_Window.pos_x+22, Promt_Window.pos_y+10, "DELETE NODE?", Font_11x18, ILI9341_RED, Promt_Window.color_on);
    sprintf(tempString, "Node ID %#04X", selected_Node_ID);
    ILI9341_WriteString(Promt_Window.pos_x+14, Promt_Window.pos_y+35, tempString, Font_11x18, ILI9341_BLACK, Promt_Window.color_on);
    ILI9341_UpdateButton(&Promt_Confirm);
    ILI9341_WriteString(Promt_Confirm.pos_x+7, Promt_Confirm.pos_y+6, "Confirm", Font_11x18, ILI9341_WHITE, Promt_Confirm.color_on);
  }
}

//-------------------------------------------------------------------------------------------------------------------

void LCD_Print_Join_Request_Page(void)
{
  memset(arrayNodeDisplay, '\0', sizeof(arrayNodeDisplay));
  Link_Struct_t link_stored;

  number_of_Node_inQueue = MAX_NODE - (uint8_t)uxQueueSpacesAvailable(link_queue);
  sprintf(tempString, "Join Request (%i)", number_of_Node_inQueue);

  if (is_page_change == true) ILI9341_FillScreen(ILI9341_BLACK);

  if (is_promt_window_on == true)   return;

  ILI9341_WriteString(80, 21, tempString, Font_11x18, ILI9341_YELLOW, ILI9341_BLACK);

  if (is_page_change == true) ILI9341_UpdateButton(&Back_Top_Left);
  ILI9341_WriteString(Back_Top_Left.pos_x-10, Back_Top_Left.pos_y-13, "<", Font_16x26, ILI9341_BLACK, Back_Top_Left.color_on);

  ILI9341_DrawRectangle(Button1.pos_x, Button1.pos_y, Button1.shape_w, Button1.shape_h, ILI9341_YELLOW);
  ILI9341_DrawRectangle(Button2.pos_x, Button2.pos_y, Button2.shape_w, Button2.shape_h, ILI9341_YELLOW);
  ILI9341_DrawRectangle(Button3.pos_x, Button3.pos_y, Button3.shape_w, Button3.shape_h, ILI9341_YELLOW);
  ILI9341_DrawRectangle(Button4.pos_x, Button4.pos_y, Button4.shape_w, Button4.shape_h, ILI9341_YELLOW);

  if (number_of_Node_inQueue >= 1)
  {
    xQueueReceive(link_queue, &link_stored, 100);
    arrayNodeDisplay[0] = link_stored.Node_ID;
    sprintf(tempString, "Node ID: %#04X", link_stored.Node_ID);
    ILI9341_WriteString(Button1.pos_x+22, Button1.pos_y+10, tempString, Font_7x10, ILI9341_GREEN, ILI9341_BLACK);
    sprintf(tempString, "Node Status: %d", link_stored.Node_Status);
    ILI9341_WriteString(Button1.pos_x+10, Button1.pos_y+35, tempString, Font_7x10, ILI9341_LIGHTBLUE, ILI9341_BLACK);
    sprintf(tempString, "Node Batt: % 4d mV", link_stored.Node_Battery_Voltage);
    ILI9341_WriteString(Button1.pos_x+10, Button1.pos_y+55, tempString, Font_7x10, ILI9341_LIGHTBLUE, ILI9341_BLACK);
    sprintf(tempString, "Node Period: % 4d s", link_stored.Node_Period);
    ILI9341_WriteString(Button1.pos_x+10, Button1.pos_y+75, tempString, Font_7x10, ILI9341_LIGHTBLUE, ILI9341_BLACK);
    xQueueSend(link_queue, &link_stored, 100);
  }
  if (number_of_Node_inQueue >= 2)
  {
    xQueueReceive(link_queue, &link_stored, 100);
    arrayNodeDisplay[1] = link_stored.Node_ID;
    sprintf(tempString, "Node ID: %#04X", link_stored.Node_ID);
    ILI9341_WriteString(Button2.pos_x+22, Button2.pos_y+10, tempString, Font_7x10, ILI9341_GREEN, ILI9341_BLACK);
    sprintf(tempString, "Node Status: %d", link_stored.Node_Status);
    ILI9341_WriteString(Button2.pos_x+10, Button2.pos_y+35, tempString, Font_7x10, ILI9341_LIGHTBLUE, ILI9341_BLACK);
    sprintf(tempString, "Node Batt: % 4d mV", link_stored.Node_Battery_Voltage);
    ILI9341_WriteString(Button2.pos_x+10, Button2.pos_y+55, tempString, Font_7x10, ILI9341_LIGHTBLUE, ILI9341_BLACK);
    sprintf(tempString, "Node Period: % 4d s", link_stored.Node_Period);
    ILI9341_WriteString(Button2.pos_x+10, Button2.pos_y+75, tempString, Font_7x10, ILI9341_LIGHTBLUE, ILI9341_BLACK);
    xQueueSend(link_queue, &link_stored, 100);
  }
  if (number_of_Node_inQueue >= 3)
  {
    xQueueReceive(link_queue, &link_stored, 100);
    arrayNodeDisplay[2] = link_stored.Node_ID;
    sprintf(tempString, "Node ID: %#04X", link_stored.Node_ID);
    ILI9341_WriteString(Button3.pos_x+22, Button3.pos_y+10, tempString, Font_7x10, ILI9341_GREEN, ILI9341_BLACK);
    sprintf(tempString, "Node Status: %d", link_stored.Node_Status);
    ILI9341_WriteString(Button3.pos_x+10, Button3.pos_y+35, tempString, Font_7x10, ILI9341_LIGHTBLUE, ILI9341_BLACK);
    sprintf(tempString, "Node Batt: % 4d mV", link_stored.Node_Battery_Voltage);
    ILI9341_WriteString(Button3.pos_x+10, Button3.pos_y+55, tempString, Font_7x10, ILI9341_LIGHTBLUE, ILI9341_BLACK);
    sprintf(tempString, "Node Period: % 4d s", link_stored.Node_Period);
    ILI9341_WriteString(Button3.pos_x+10, Button3.pos_y+75, tempString, Font_7x10, ILI9341_LIGHTBLUE, ILI9341_BLACK);
    xQueueSend(link_queue, &link_stored, 100);
  }
  if (number_of_Node_inQueue >= 4)
  {
    xQueueReceive(link_queue, &link_stored, 100);
    arrayNodeDisplay[3] = link_stored.Node_ID;
    sprintf(tempString, "Node ID: %#04X", link_stored.Node_ID);
    ILI9341_WriteString(Button4.pos_x+22, Button4.pos_y+10, tempString, Font_7x10, ILI9341_GREEN, ILI9341_BLACK);
    sprintf(tempString, "Node Status: %d", link_stored.Node_Status);
    ILI9341_WriteString(Button4.pos_x+10, Button4.pos_y+35, tempString, Font_7x10, ILI9341_LIGHTBLUE, ILI9341_BLACK);
    sprintf(tempString, "Node Batt: % 4d mV", link_stored.Node_Battery_Voltage);
    ILI9341_WriteString(Button4.pos_x+10, Button4.pos_y+55, tempString, Font_7x10, ILI9341_LIGHTBLUE, ILI9341_BLACK);
    sprintf(tempString, "Node Period: % 4d s", link_stored.Node_Period);
    ILI9341_WriteString(Button4.pos_x+10, Button4.pos_y+75, tempString, Font_7x10, ILI9341_LIGHTBLUE, ILI9341_BLACK);
    xQueueSend(link_queue, &link_stored, 100);
  }

  is_page_change = false;
}

void LCD_Join_Request_Page_Handle(const uint16_t x, const uint16_t y)
{
  if (is_promt_window_on == true)
  {
    if (ILI9341_checkButton(x, y, &Promt_Accept, false) == true)
    {
      ResponsePacket_t resp_packet;
      Link_Struct_t link_2_store;
      is_Node_ID_inResponseQueue(selected_Node_ID, true);
      is_Node_ID_inLinkQueue(selected_Node_ID, false);
      xQueueReceive(link_queue, &link_2_store, 100);
      number_of_Node_inQueue = MAX_NODE - (uint8_t)uxQueueSpacesAvailable(link_queue);
      if (number_of_Node_inQueue != MAX_NODE)   logPC("Link Queue has %d Node(s)\n", number_of_Node_inQueue);
      else                                      logPC("Link Queue Full\n");
      resp_packet.Packet_ID = PACKET_ID_2;
      resp_packet.Target_Node_ID = selected_Node_ID;
      resp_packet.Target_Node_Status = 4U;
      resp_packet.Target_Node_Period = 180U;
      resp_packet.Target_Node_Response = (uint16_t)(((uint16_t)(LINK_ACCEPT << 8) & 0xFF00) | LINK_ACK);
      xQueueSend(response_queue, &resp_packet, 100);
      number_of_Response_Packet_inQueue = 5U - (uint8_t)uxQueueSpacesAvailable(response_queue);
      if (number_of_Response_Packet_inQueue != 5U)    logPC("Response Queue has %d packet(s)\n", number_of_Response_Packet_inQueue);
      else                                            logPC("Response Queue Full\n");
      App_Add_Node_To_Network(link_2_store);
      ILI9341_FillRectangle(Promt_Window.pos_x, Promt_Window.pos_y, Promt_Window.shape_w, Promt_Window.shape_h, ILI9341_BLACK);
      is_page_change = true;
      LCD_Print_Join_Request_Page();
      is_promt_window_on = false;
    }
    else if (ILI9341_checkButton(x, y, &Promt_Reject, false) == true)
    {
      ResponsePacket_t resp_packet;
      is_Node_ID_inResponseQueue(selected_Node_ID, true);
      is_Node_ID_inLinkQueue(selected_Node_ID, true);
      number_of_Node_inQueue = MAX_NODE - (uint8_t)uxQueueSpacesAvailable(link_queue);
      if (number_of_Node_inQueue != MAX_NODE)   logPC("Link Queue has %d Node(s)\n", number_of_Node_inQueue);
      else                                      logPC("Link Queue Full\n");
      resp_packet.Packet_ID = PACKET_ID_2;
      resp_packet.Target_Node_ID = selected_Node_ID;
      resp_packet.Target_Node_Status = 16U;
      resp_packet.Target_Node_Period = 180U;
      resp_packet.Target_Node_Response = (uint16_t)(((uint16_t)(LINK_REJECT << 8) & 0xFF00) | LINK_ACK);
      xQueueSend(response_queue, &resp_packet, 100);
      number_of_Response_Packet_inQueue = 5U - (uint8_t)uxQueueSpacesAvailable(response_queue);
      if (number_of_Response_Packet_inQueue != 5U)    logPC("Response Queue has %d packet(s)\n", number_of_Response_Packet_inQueue);
      else                                            logPC("Response Queue Full\n");
      ILI9341_FillRectangle(Promt_Window.pos_x, Promt_Window.pos_y, Promt_Window.shape_w,Promt_Window.shape_h, ILI9341_BLACK);
      is_page_change = true;
      LCD_Print_Join_Request_Page();
      is_promt_window_on = false;
    }
    else if (ILI9341_checkButton(x, y, &Promt_Window, false) == false)
    {
      ILI9341_FillRectangle(Promt_Window.pos_x, Promt_Window.pos_y, Promt_Window.shape_w,Promt_Window.shape_h, ILI9341_BLACK);
      LCD_Print_Join_Request_Page();
      is_promt_window_on = false;
    }
    return;
  }

  if (ILI9341_checkButton(x, y, &Back_Top_Left, false) == true)
  {
    Current_Page = MAIN_PAGE;
    is_page_change = true;
  }

  if (number_of_Node_inQueue == 0)  return;

  if      ((ILI9341_checkButton(x, y, &Button1, false) == true) && (arrayNodeDisplay[0] != 0U))
  {
    selected_Node_ID = arrayNodeDisplay[0];
    LCD_Print_Promt_Window();
  }
  else if ((ILI9341_checkButton(x, y, &Button2, false) == true) && (arrayNodeDisplay[1] != 0U))
  {
    selected_Node_ID = arrayNodeDisplay[1];
    LCD_Print_Promt_Window();
  }
  else if ((ILI9341_checkButton(x, y, &Button3, false) == true) && (arrayNodeDisplay[2] != 0U))
  {
    selected_Node_ID = arrayNodeDisplay[2];
    LCD_Print_Promt_Window();
  }
  else if ((ILI9341_checkButton(x, y, &Button4, false) == true) && (arrayNodeDisplay[3] != 0U))
  {
    selected_Node_ID = arrayNodeDisplay[3];
    LCD_Print_Promt_Window();
  }
}

//-------------------------------------------------------------------------------------------------------------------

void LCD_Print_Main_Page(void)
{
  static RTC_TimeTypeDef sTime = {0};
  static RTC_DateTypeDef sDate = {0};

  HAL_RTC_GetTime(&hrtc, &sTime, RTC_FORMAT_BIN);
  HAL_RTC_GetDate(&hrtc, &sDate, RTC_FORMAT_BIN);

  memset(tempString, '\0', sizeof(tempString));

  if (is_page_change == true) ILI9341_FillScreen(ILI9341_BLACK);

  sprintf(tempString, "SIM:%s-%s", (is_4G_or_WiFi==USE_4G)? ("ON"):("OFF"), (is_4G_connected==true)? ("CON "):("DIS "));
  ILI9341_WriteString(20, 10, tempString, Font_7x10, ILI9341_YELLOW, ILI9341_BLACK);
  sprintf(tempString, "WIFI:%s-%s", (is_4G_or_WiFi==USE_WIFI)? ("ON"):("OFF"), (is_WiFi_connected==true)? ("CON "):("DIS "));
  ILI9341_WriteString(125, 10, tempString, Font_7x10, ILI9341_YELLOW, ILI9341_BLACK);
  sprintf(tempString, "MQTT:%s", (is_MQTT_connected==true)? ("CON"):("DIS"));
  ILI9341_WriteString(244, 10, tempString, Font_7x10, ILI9341_YELLOW, ILI9341_BLACK);

  sprintf(tempString, "%02i:%02i", sTime.Hours, sTime.Minutes);
  ILI9341_WriteString(120, 40, tempString, Font_16x26, ILI9341_PINK, ILI9341_BLACK);
  sprintf(tempString, "%02i/%02i/20%02i", sDate.Date, sDate.Month, sDate.Year);
  ILI9341_WriteString(105, 75, tempString, Font_11x18, ILI9341_DARKBLUE, ILI9341_BLACK);

  if (is_page_change == false) return;

  ILI9341_WriteString(80, 100, "SOL GARDEN", Font_16x26, ILI9341_YELLOW, ILI9341_BLACK);

  ILI9341_UpdateButton(&To_Join_Request_Page);
  ILI9341_WriteString(To_Join_Request_Page.pos_x-28, To_Join_Request_Page.pos_y-8, "JOIN>", Font_11x18, ILI9341_BLACK, To_Join_Request_Page.color_on);
  ILI9341_UpdateButton(&To_Network_Page);
  ILI9341_WriteString(To_Network_Page.pos_x-28, To_Network_Page.pos_y-8, "<NETW", Font_11x18, ILI9341_BLACK, To_Network_Page.color_on);
  ILI9341_UpdateButton(&To_Control_Page);
  ILI9341_WriteString(To_Control_Page.pos_x-38, To_Control_Page.pos_y-8, "CONTROL", Font_11x18, ILI9341_BLACK, To_Control_Page.color_on);

  if (is_page_change == true) {is_page_change = false;}
}

void LCD_Main_Page_Handle(const uint16_t x, const uint16_t y)
{
  if (ILI9341_checkButton(x, y, &To_Join_Request_Page, false) == true)
  {
    Current_Page = JOIN_REQUEST_PAGE;
    is_page_change = true;
  }
  else if (ILI9341_checkButton(x, y, &To_Network_Page, false) == true)
  {
    Current_Page = NETWORK_PAGE;
    is_page_change = true;
  }
  else if (ILI9341_checkButton(x, y, &To_Control_Page, false) == true)
  {
    Current_Page = CONTROL_PAGE;
    is_page_change = true;
  }
  else if ((ILI9341_checkButton(x, y, &Select_4G, false) == true) && (is_4G_or_WiFi == USE_WIFI))
  {
    is_4G_or_WiFi = USE_4G;
    if (uxTaskGetNumberOfTasks() < 6) {Task3Handle = osThreadNew(Task3Func, NULL, &Task3_attributes);}
    is_4G_connected = false;
    is_WiFi_connected = false;
    is_MQTT_connected = false;
    logPC("\tChoose 4G\tWIFI-OFF\t");
  }
  else if ((ILI9341_checkButton(x, y, &Select_WiFi, false) == true) && (is_4G_or_WiFi == USE_4G))
  {
    is_4G_or_WiFi = USE_WIFI;
    if (uxTaskGetNumberOfTasks() >= 6) {osThreadTerminate(Task3Handle);}
    SIM_Deinit();
    is_4G_connected = false;
    is_WiFi_connected = false;
    is_MQTT_connected = false;
    logPC("\tChoose WiFi\tWIFI-ON\t");
  }
}

//-------------------------------------------------------------------------------------------------------------------

void LCD_Print_Network_Page(void)
{
  sprintf(tempString, "Network (%i)", number_of_Node_inNetwork);
  memset(arrayNodeDisplay, '\0', sizeof(arrayNodeDisplay));

  if (is_page_change == true) ILI9341_FillScreen(ILI9341_BLACK);

  if (is_page_change == true) ILI9341_UpdateButton(&FakeHehe);

  ILI9341_WriteString(105, 21, tempString, Font_11x18, ILI9341_YELLOW, ILI9341_BLACK);

  if (is_page_change == true) ILI9341_UpdateButton(&Back_Top_Right);
  ILI9341_WriteString(Back_Top_Right.pos_x-8, Back_Top_Right.pos_y-13, ">", Font_16x26, ILI9341_BLACK, Back_Top_Right.color_on);

  ILI9341_DrawRectangle(Button1.pos_x, Button1.pos_y, Button1.shape_w, Button1.shape_h, ILI9341_YELLOW);
  ILI9341_DrawRectangle(Button2.pos_x, Button2.pos_y, Button2.shape_w, Button2.shape_h, ILI9341_YELLOW);
  ILI9341_DrawRectangle(Button3.pos_x, Button3.pos_y, Button3.shape_w, Button3.shape_h, ILI9341_YELLOW);
  ILI9341_DrawRectangle(Button4.pos_x, Button4.pos_y, Button4.shape_w, Button4.shape_h, ILI9341_YELLOW);

  uint8_t loop = (number_of_Node_inNetwork >= 4)? (4):(number_of_Node_inNetwork);
  uint8_t idx = (uint8_t)get_random_value(0, MAX_NODE);
  for (uint8_t j = 0; j < loop; j++)
  {
    while (Node_Table[idx].Link.Node_ID == 0)
    {
      idx++;
      if (idx >= MAX_NODE)  idx = 0;
    }

    if (j == 0)
    {
      arrayNodeDisplay[0] = Node_Table[idx].Link.Node_ID;
      sprintf(tempString, "Node ID: %#04X", Node_Table[idx].Link.Node_ID);
      ILI9341_WriteString(Button1.pos_x+22, Button1.pos_y+10, tempString, Font_7x10, ILI9341_GREEN, ILI9341_BLACK);
      sprintf(tempString, "Node Status: %d", Node_Table[idx].Link.Node_Status);
      ILI9341_WriteString(Button1.pos_x+10, Button1.pos_y+35, tempString, Font_7x10, ILI9341_LIGHTBLUE, ILI9341_BLACK);
      sprintf(tempString, "Node Batt: % 4d mV", Node_Table[idx].Link.Node_Battery_Voltage);
      ILI9341_WriteString(Button1.pos_x+10, Button1.pos_y+55, tempString, Font_7x10, ILI9341_LIGHTBLUE, ILI9341_BLACK);
      sprintf(tempString, "Node Period: % 4d s", Node_Table[idx].Link.Node_Period);
      ILI9341_WriteString(Button1.pos_x+10, Button1.pos_y+75, tempString, Font_7x10, ILI9341_LIGHTBLUE, ILI9341_BLACK);
    }
    else if (j == 1)
    {
      arrayNodeDisplay[1] = Node_Table[idx].Link.Node_ID;
      sprintf(tempString, "Node ID: %#04X", Node_Table[idx].Link.Node_ID);
      ILI9341_WriteString(Button2.pos_x+22, Button2.pos_y+10, tempString, Font_7x10, ILI9341_GREEN, ILI9341_BLACK);
      sprintf(tempString, "Node Status: %d", Node_Table[idx].Link.Node_Status);
      ILI9341_WriteString(Button2.pos_x+10, Button2.pos_y+35, tempString, Font_7x10, ILI9341_LIGHTBLUE, ILI9341_BLACK);
      sprintf(tempString, "Node Batt: % 4d mV", Node_Table[idx].Link.Node_Battery_Voltage);
      ILI9341_WriteString(Button2.pos_x+10, Button2.pos_y+55, tempString, Font_7x10, ILI9341_LIGHTBLUE, ILI9341_BLACK);
      sprintf(tempString, "Node Period: % 4d s", Node_Table[idx].Link.Node_Period);
      ILI9341_WriteString(Button2.pos_x+10, Button2.pos_y+75, tempString, Font_7x10, ILI9341_LIGHTBLUE, ILI9341_BLACK);
    }
    else if (j == 2)
    {
      arrayNodeDisplay[2] = Node_Table[idx].Link.Node_ID;
      sprintf(tempString, "Node ID: %#04X", Node_Table[idx].Link.Node_ID);
      ILI9341_WriteString(Button3.pos_x+22, Button3.pos_y+10, tempString, Font_7x10, ILI9341_GREEN, ILI9341_BLACK);
      sprintf(tempString, "Node Status: %d", Node_Table[idx].Link.Node_Status);
      ILI9341_WriteString(Button3.pos_x+10, Button3.pos_y+35, tempString, Font_7x10, ILI9341_LIGHTBLUE, ILI9341_BLACK);
      sprintf(tempString, "Node Batt: % 4d mV", Node_Table[idx].Link.Node_Battery_Voltage);
      ILI9341_WriteString(Button3.pos_x+10, Button3.pos_y+55, tempString, Font_7x10, ILI9341_LIGHTBLUE, ILI9341_BLACK);
      sprintf(tempString, "Node Period: % 4d s", Node_Table[idx].Link.Node_Period);
      ILI9341_WriteString(Button3.pos_x+10, Button3.pos_y+75, tempString, Font_7x10, ILI9341_LIGHTBLUE, ILI9341_BLACK);
    }
    else if (j == 3)
    {
      arrayNodeDisplay[3] = Node_Table[idx].Link.Node_ID;
      sprintf(tempString, "Node ID: %#04X", Node_Table[idx].Link.Node_ID);
      ILI9341_WriteString(Button4.pos_x+22, Button4.pos_y+10, tempString, Font_7x10, ILI9341_GREEN, ILI9341_BLACK);
      sprintf(tempString, "Node Status: %d", Node_Table[idx].Link.Node_Status);
      ILI9341_WriteString(Button4.pos_x+10, Button4.pos_y+35, tempString, Font_7x10, ILI9341_LIGHTBLUE, ILI9341_BLACK);
      sprintf(tempString, "Node Batt: % 4d mV", Node_Table[idx].Link.Node_Battery_Voltage);
      ILI9341_WriteString(Button4.pos_x+10, Button4.pos_y+55, tempString, Font_7x10, ILI9341_LIGHTBLUE, ILI9341_BLACK);
      sprintf(tempString, "Node Period: % 4d s", Node_Table[idx].Link.Node_Period);
      ILI9341_WriteString(Button4.pos_x+10, Button4.pos_y+75, tempString, Font_7x10, ILI9341_LIGHTBLUE, ILI9341_BLACK);
    }

    idx++;
  }
  is_page_change = false;
}

void LCD_Network_Page_Handle(const uint16_t x, const uint16_t y)
{
  if ((ILI9341_checkButton(x, y, &FakeHehe, false) == true))
  {
    Current_Page = FAKE_PAGE;
    is_page_change = true;
    return;
  }
  if (ILI9341_checkButton(x, y, &Back_Top_Right, false) == true)
  {
    Current_Page = MAIN_PAGE;
    is_page_change = true;
  }
  else if ((ILI9341_checkButton(x, y, &Button1, false) == true) && (arrayNodeDisplay[0] != 0U))
  {
    selected_Node_ID = arrayNodeDisplay[0];
    Current_Page = NODE_PAGE;
    is_page_change = true;
  }
  else if ((ILI9341_checkButton(x, y, &Button2, false) == true) && (arrayNodeDisplay[1] != 0U))
  {
    selected_Node_ID = arrayNodeDisplay[1];
    Current_Page = NODE_PAGE;
    is_page_change = true;
  }
  else if ((ILI9341_checkButton(x, y, &Button3, false) == true) && (arrayNodeDisplay[2] != 0U))
  {
    selected_Node_ID = arrayNodeDisplay[2];
    Current_Page = NODE_PAGE;
    is_page_change = true;
  }
  else if ((ILI9341_checkButton(x, y, &Button4, false) == true) && (arrayNodeDisplay[3] != 0U))
  {
    selected_Node_ID = arrayNodeDisplay[3];
    Current_Page = NODE_PAGE;
    is_page_change = true;
  }
}

//-------------------------------------------------------------------------------------------------------------------

void LCD_Print_Node_Page(void)
{
  if (is_page_change == true) ILI9341_FillScreen(ILI9341_BLACK);

  if (is_promt_window_on == true)   return;

  Data_Struct_t data_stored = Node_Table[get_Index_from_Node_ID(selected_Node_ID)];

  if (is_page_change == true) ILI9341_UpdateButton(&Back_Top_Right);
  ILI9341_WriteString(Back_Top_Right.pos_x-8, Back_Top_Right.pos_y-13, ">", Font_16x26, ILI9341_BLACK, Back_Top_Right.color_on);

  if (is_page_change == true) ILI9341_UpdateButton(&Delete);
  ILI9341_WriteString(Delete.pos_x-5, Delete.pos_y-8, "X", Font_11x18, ILI9341_WHITE, Delete.color_on);

  sprintf(tempString, "NODE %#04X", selected_Node_ID);
  ILI9341_WriteString(105, 14, tempString, Font_11x18, ILI9341_YELLOW, ILI9341_BLACK);

  switch (data_stored.Link.Node_Status)
  {
    case (2U): {
      ILI9341_WriteString(75, 35, "Node Status: LINK", Font_11x18, ILI9341_CYAN, ILI9341_BLACK);
      break;
    }
    case (4U): {
      ILI9341_WriteString(65, 35, "Node Status: NORMAL", Font_11x18, ILI9341_GREEN, ILI9341_BLACK);
      break;
    }
    case (8U): {
      ILI9341_WriteString(75, 35, "Node Status: RETRY", Font_11x18, ILI9341_ORANGE, ILI9341_BLACK);
      break;
    }
    default: {
      ILI9341_WriteString(60, 35, "Node Status: UNKOWN", Font_11x18, ILI9341_RED, ILI9341_BLACK);
      break;
    }
  }

  sprintf(tempString, "Node Batt: % 4d mV", data_stored.Link.Node_Battery_Voltage);
  ILI9341_WriteString(15, 60, tempString, Font_7x10, ILI9341_YELLOW, ILI9341_BLACK);

  sprintf(tempString, "Node Period: % 4d s", data_stored.Link.Node_Period);
  ILI9341_WriteString(175, 60, tempString, Font_7x10, ILI9341_YELLOW, ILI9341_BLACK);

  if (data_stored.Link.Node_Status != 4U) {is_page_change = false; return;}

  sprintf(tempString, "Soil Temp.: % 2.1f dC", (float)(data_stored.Node_Soil_Temperature/10.0));
  ILI9341_WriteString(15, 100, tempString, Font_7x10, ILI9341_RED, ILI9341_BLACK);

  sprintf(tempString, "Air Temp.: % 2.1f dC", (float)(data_stored.Node_Air_Temperature/10.0));
  ILI9341_WriteString(175, 100, tempString, Font_7x10, ILI9341_RED, ILI9341_BLACK);

  sprintf(tempString, "Soil Humd.: % 2.1f %%RH", (float)(data_stored.Node_Soil_Humidity/10.0));
  ILI9341_WriteString(15, 120, tempString, Font_7x10, ILI9341_ORANGE, ILI9341_BLACK);

  sprintf(tempString, "Air Humd.: % 2.1f %%RH", (float)(data_stored.Node_Air_Humidity/10.0));
  ILI9341_WriteString(175, 120, tempString, Font_7x10, ILI9341_ORANGE, ILI9341_BLACK);

  sprintf(tempString, "Salinity: %d uS/cm", data_stored.Node_Salinity);
  ILI9341_WriteString(15, 140, tempString, Font_7x10, ILI9341_YELLOW, ILI9341_BLACK);

  sprintf(tempString, "Conductivity: %d uS/cm", data_stored.Node_Conductivity);
  ILI9341_WriteString(15, 160, tempString, Font_7x10, ILI9341_LIGHTGREEN, ILI9341_BLACK);

  sprintf(tempString, "pH: % 2.1f pH", (float)(data_stored.Node_pH/10.0));
  ILI9341_WriteString(15, 180, tempString, Font_7x10, ILI9341_LIGHTBLUE, ILI9341_BLACK);

  sprintf(tempString, "N: %d mg/kg", (uint16_t)(data_stored.Node_N/10));
  ILI9341_WriteString(175, 180, tempString, Font_7x10, ILI9341_LIGHTBLUE, ILI9341_BLACK);

  sprintf(tempString, "P: %d mg/kg", (uint16_t)(data_stored.Node_P/10));
  ILI9341_WriteString(15, 200, tempString, Font_7x10, ILI9341_PINK, ILI9341_BLACK);

  sprintf(tempString, "K: %d mg/kg", (uint16_t)(data_stored.Node_K/10));
  ILI9341_WriteString(175, 200, tempString, Font_7x10, ILI9341_PINK, ILI9341_BLACK);

  is_page_change = false;
}

void LCD_Node_Page_Handle(const uint16_t x, const uint16_t y)
{
  if (is_promt_window_on == true)
  {
    if (ILI9341_checkButton(x, y, &Promt_Confirm, false) == true)
    {
      App_Delete_Node_From_Network(selected_Node_ID);
      ILI9341_FillRectangle(Promt_Window.pos_x, Promt_Window.pos_y, Promt_Window.shape_w,Promt_Window.shape_h, ILI9341_BLACK);
      is_page_change = true;
      Current_Page = NETWORK_PAGE;
      is_promt_window_on = false;
    }
    else if (ILI9341_checkButton(x, y, &Promt_Window, false) == false)
    {
      ILI9341_FillRectangle(Promt_Window.pos_x, Promt_Window.pos_y, Promt_Window.shape_w,Promt_Window.shape_h, ILI9341_BLACK);
      Current_Page = NODE_PAGE;
      is_promt_window_on = false;
    }
    return;
  }

  if (ILI9341_checkButton(x, y, &Back_Top_Right, false) == true)
  {
    Current_Page = NETWORK_PAGE;
    is_page_change = true;
  }

  if (number_of_Node_inNetwork == 0)  return;

  if (ILI9341_checkButton(x, y, &Delete, false) == true)
  {
    LCD_Print_Promt_Window();
  }
}

//-------------------------------------------------------------------------------------------------------------------

void LCD_Print_Control_Page(void)
{
  if (is_page_change == true) {ILI9341_FillScreen(ILI9341_BLACK); is_page_change = false;}
  else return;

  ILI9341_UpdateButton(&To_Main_Page);
  ILI9341_WriteString(To_Main_Page.pos_x-22, To_Main_Page.pos_y-7, "MAIN", Font_11x18, ILI9341_WHITE, To_Main_Page.color_on);

  ILI9341_UpdateButton(&Button5);
  if (Button5.state == BUTTON_ON) ILI9341_WriteString(Button5.pos_x-16, Button5.pos_y-10, "ON", Font_16x26, ILI9341_BLACK, Button5.color_on);
  else                            ILI9341_WriteString(Button5.pos_x-24, Button5.pos_y-10, "OFF", Font_16x26, ILI9341_WHITE, Button5.color_off);
  ILI9341_WriteString(110, 10, "RL0", Font_11x18, ILI9341_YELLOW, ILI9341_BLACK);

  ILI9341_UpdateButton(&Button6);
  if (Button6.state == BUTTON_ON) ILI9341_WriteString(Button6.pos_x-16, Button6.pos_y-10, "ON", Font_16x26, ILI9341_BLACK, Button6.color_on);
  else                            ILI9341_WriteString(Button6.pos_x-24, Button6.pos_y-10, "OFF", Font_16x26, ILI9341_WHITE, Button6.color_off);
  ILI9341_WriteString(180, 10, "RL1", Font_11x18, ILI9341_YELLOW, ILI9341_BLACK);

  ILI9341_UpdateButton(&Button7);
  if (Button7.state == BUTTON_ON) ILI9341_WriteString(Button7.pos_x-16, Button7.pos_y-10, "ON", Font_16x26, ILI9341_BLACK, Button7.color_on);
  else                            ILI9341_WriteString(Button7.pos_x-24, Button7.pos_y-10, "OFF", Font_16x26, ILI9341_WHITE, Button7.color_off);
  ILI9341_WriteString(110, 210, "RL2", Font_11x18, ILI9341_YELLOW, ILI9341_BLACK);

  ILI9341_UpdateButton(&Button8);
  if (Button8.state == BUTTON_ON) ILI9341_WriteString(Button8.pos_x-16, Button8.pos_y-10, "ON", Font_16x26, ILI9341_BLACK, Button8.color_on);
  else                            ILI9341_WriteString(Button8.pos_x-24, Button8.pos_y-10, "OFF", Font_16x26, ILI9341_WHITE, Button8.color_off);
  ILI9341_WriteString(180, 210, "RL3", Font_11x18, ILI9341_YELLOW, ILI9341_BLACK);
}

void LCD_Control_Page_Handle(const uint16_t x, const uint16_t y)
{
  if (ILI9341_checkButton(x, y, &To_Main_Page, false) == true)
  {
    Current_Page = MAIN_PAGE;
    is_page_change = true;
  }
  else if (ILI9341_checkButton(x, y, &Button5, true) == true)
  {
    HAL_GPIO_WritePin(RL0_GPIO_Port, RL0_Pin, (Button5.state == BUTTON_ON)? (GPIO_PIN_SET):(GPIO_PIN_RESET));
    ILI9341_UpdateButton(&Button5);
    if (Button5.state == BUTTON_ON) ILI9341_WriteString(Button5.pos_x-16, Button5.pos_y-10, "ON", Font_16x26, ILI9341_BLACK, Button5.color_on);
    else                            ILI9341_WriteString(Button5.pos_x-24, Button5.pos_y-10, "OFF", Font_16x26, ILI9341_WHITE, Button5.color_off);
  }
  else if (ILI9341_checkButton(x, y, &Button6, true) == true)
  {
    HAL_GPIO_WritePin(RL1_GPIO_Port, RL1_Pin, (Button6.state == BUTTON_ON)? (GPIO_PIN_SET):(GPIO_PIN_RESET));
    ILI9341_UpdateButton(&Button6);
    if (Button6.state == BUTTON_ON) ILI9341_WriteString(Button6.pos_x-16, Button6.pos_y-10, "ON", Font_16x26, ILI9341_BLACK, Button6.color_on);
    else                            ILI9341_WriteString(Button6.pos_x-24, Button6.pos_y-10, "OFF", Font_16x26, ILI9341_WHITE, Button6.color_off);
  }
  else if (ILI9341_checkButton(x, y, &Button7, true) == true)
  {
    HAL_GPIO_WritePin(RL2_GPIO_Port, RL2_Pin, (Button7.state == BUTTON_ON)? (GPIO_PIN_SET):(GPIO_PIN_RESET));
    ILI9341_UpdateButton(&Button7);
    if (Button7.state == BUTTON_ON) ILI9341_WriteString(Button7.pos_x-16, Button7.pos_y-10, "ON", Font_16x26, ILI9341_BLACK, Button7.color_on);
    else                            ILI9341_WriteString(Button7.pos_x-24, Button7.pos_y-10, "OFF", Font_16x26, ILI9341_WHITE, Button7.color_off);
  }
  else if (ILI9341_checkButton(x, y, &Button8, true) == true)
  {
    HAL_GPIO_WritePin(RL3_GPIO_Port, RL3_Pin, (Button8.state == BUTTON_ON)? (GPIO_PIN_SET):(GPIO_PIN_RESET));
    ILI9341_UpdateButton(&Button8);
    if (Button8.state == BUTTON_ON) ILI9341_WriteString(Button8.pos_x-16, Button8.pos_y-10, "ON", Font_16x26, ILI9341_BLACK, Button8.color_on);
    else                            ILI9341_WriteString(Button8.pos_x-24, Button8.pos_y-10, "OFF", Font_16x26, ILI9341_WHITE, Button8.color_off);
  }
}

//-------------------------------------------------------------------------------------------------------------------

void LCD_Print_Fake_Page(void)
{
  if (is_page_change == true) ILI9341_FillScreen(ILI9341_BLACK);

  if (is_page_change == true) ILI9341_UpdateButton(&Delete);
  ILI9341_WriteString(Delete.pos_x-5, Delete.pos_y-8, "X", Font_11x18, ILI9341_WHITE, Delete.color_on);

  if (is_page_change == true) ILI9341_UpdateButton(&Back_Top_Right);
  ILI9341_WriteString(Back_Top_Right.pos_x-8, Back_Top_Right.pos_y-13, ">", Font_16x26, ILI9341_BLACK, Back_Top_Right.color_on);

  ILI9341_WriteString(105, 14, "NODE 0X1303", Font_11x18, ILI9341_YELLOW, ILI9341_BLACK);

  ILI9341_WriteString(65, 35, "Node Status: NORMAL", Font_11x18, ILI9341_GREEN, ILI9341_BLACK);

  sprintf(tempString, "Node Batt: % 4d mV", 8246);
  ILI9341_WriteString(15, 60, tempString, Font_7x10, ILI9341_YELLOW, ILI9341_BLACK);

  sprintf(tempString, "Node Period: % 4d s", 240);
  ILI9341_WriteString(175, 60, tempString, Font_7x10, ILI9341_YELLOW, ILI9341_BLACK);

  sprintf(tempString, "Soil Temp.: % 2.1f dC", 32.6);
  ILI9341_WriteString(15, 100, tempString, Font_7x10, ILI9341_RED, ILI9341_BLACK);

  sprintf(tempString, "Air Temp.: % 2.1f dC", 34.4);
  ILI9341_WriteString(175, 100, tempString, Font_7x10, ILI9341_RED, ILI9341_BLACK);

  sprintf(tempString, "Soil Humd.: % 2.1f %%RH", 60.6);
  ILI9341_WriteString(15, 120, tempString, Font_7x10, ILI9341_ORANGE, ILI9341_BLACK);

  sprintf(tempString, "Air Humd.: % 2.1f %%RH", 65.0);
  ILI9341_WriteString(175, 120, tempString, Font_7x10, ILI9341_ORANGE, ILI9341_BLACK);

  sprintf(tempString, "Salinity: %d uS/cm", 2468);
  ILI9341_WriteString(15, 140, tempString, Font_7x10, ILI9341_YELLOW, ILI9341_BLACK);

  sprintf(tempString, "Conductivity: %d uS/cm", 2514);
  ILI9341_WriteString(15, 160, tempString, Font_7x10, ILI9341_LIGHTGREEN, ILI9341_BLACK);

  sprintf(tempString, "pH: % 2.1f pH", 8.5);
  ILI9341_WriteString(15, 180, tempString, Font_7x10, ILI9341_LIGHTBLUE, ILI9341_BLACK);

  sprintf(tempString, "N: %d mg/kg", 33);
  ILI9341_WriteString(175, 180, tempString, Font_7x10, ILI9341_LIGHTBLUE, ILI9341_BLACK);

  sprintf(tempString, "P: %d mg/kg", 53);
  ILI9341_WriteString(15, 200, tempString, Font_7x10, ILI9341_PINK, ILI9341_BLACK);

  sprintf(tempString, "K: %d mg/kg", 80);
  ILI9341_WriteString(175, 200, tempString, Font_7x10, ILI9341_PINK, ILI9341_BLACK);

  is_page_change = false;
}

void LCD_Fake_Page_Handle(const uint16_t x, const uint16_t y)
{
  if (ILI9341_checkButton(x, y, &Back_Top_Right, false) == true)
  {
    Current_Page = NETWORK_PAGE;
    is_page_change = true;
  }
}

/* USER CODE END Application */
